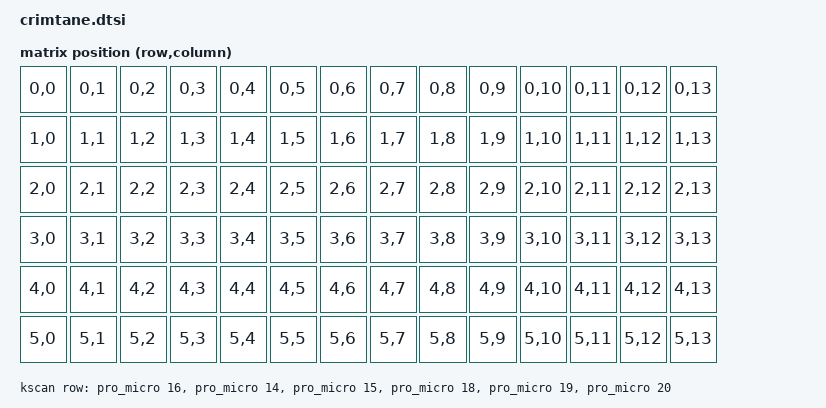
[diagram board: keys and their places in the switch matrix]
// This file was generated from a template. Edit it to match your keyboard.
// See https://zmk.dev/docs/development/hardware-integration/new-shield for more
// instructions.

#include <dt-bindings/zmk/matrix_transform.h>

#include "crimtane-layouts.dtsi"

/ {
    chosen {
        zmk,kscan = &kscan;
        zmk,matrix_transform = &default_transform;
    };

    default_transform: default_transform {
        compatible = "zmk,matrix-transform";
        columns = <14>;
        rows = <6>;
//  nice!nano_v2
// | 024,010 | 100,010 | 011,010 | 104,010 | 106,010 | 022,010 | 020,010 |	| 106,010 | 104,010 | 011,010 | 100,010 | 024,010 | 022,010 | 020,010 |
// | 024,111 | 100,111 | 011,111 | 104,111 | 106,111 | 022,111 |			  | 104,111 | 011,111 | 100,111 | 024,111 | 022,111 | 020,111 |
// | 024,113 | 100,113 | 011,113 | 104,113 | 106,113 | 022,113 | 020,113 |	| 106,113 | 104,113 | 011,113 | 100,113 | 024,113 | 022,113 | 020,113 |
// | 024,115 | 100,115 | 011,115 | 104,115 | 106,115 | 022,115 | 020,115 |	| 106,115 | 104,115 | 011,115 | 100,115 | 024,115 | 022,115 | 020,115 |
// | 024,002 | 100,002 | 011,002 | 104,002 | 106,002 | 022,002 |			  | 104,002 | 011,002 | 100,002 | 024,002 | 022,002 | 020,002 |
// | 024,029 | 100,029 | 011,029 | 104,029 | 106,029 |	       | 020,029 |	| 106,029 |         | 011,029 | 100,029 | 024,029 | 022,029 | 020,029 |
//  pro_micro
// | 5,16 |  6,16 |  7,16 |  8,16 |  9,16 |  4,16 |  3,16 |   |  9,16 |  8,16 |  7,16 |  6,16 |  5,16 |  4,16 |  3,16 |
// | 5,14 |  6,14 |  7,14 |  8,14 |  9,14 |  4,14 |       |           |  8,14 |  7,14 |  6,14 |  5,14 |  4,14 |  3,14 |
// | 5,15 |  6,15 |  7,15 |  8,15 |  9,15 |  4,15 |  3,15 |   |  9,15 |  8,15 |  7,15 |  6,15 |  5,15 |  4,15 |  3,15 |
// | 5,18 |  6,18 |  7,18 |  8,18 |  9,18 |  4,18 |  3,18 |   |  9,18 |  8,18 |  7,18 |  6,18 |  5,18 |  4,18 |  3,18 |
// | 5,19 |  6,19 |  7,19 |  8,19 |  9,19 |  4,19 |       |           |  8,19 |  7,19 |  6,19 |  5,19 |  4,19 |  3,19 |
// | 5,20 |  6,20 |  7,20 |  8,20 |  9,20 |       |  3,20 |   |  9,20 |       |  7,20 |  6,20 |  5,20 |  4,20 |  3,20 |

        map = <
RC(0,0) RC(0,1) RC(0,2) RC(0,3) RC(0,4) RC(0,5) RC(0,6) 	RC(0,7) RC(0,8) RC(0,9) RC(0,10) RC(0,11) RC(0,12) RC(0,13)
RC(1,0) RC(1,1) RC(1,2) RC(1,3) RC(1,4) RC(1,5) RC(1,6)	 	RC(1,7)	RC(1,8) RC(1,9) RC(1,10) RC(1,11) RC(1,12) RC(1,13)
RC(2,0) RC(2,1) RC(2,2) RC(2,3) RC(2,4) RC(2,5) RC(2,6) 	RC(2,7) RC(2,8) RC(2,9) RC(2,10) RC(2,11) RC(2,12) RC(2,13)
RC(3,0) RC(3,1) RC(3,2) RC(3,3) RC(3,4) RC(3,5) RC(3,6) 	RC(3,7) RC(3,8) RC(3,9) RC(3,10) RC(3,11) RC(3,12) RC(3,13)
RC(4,0) RC(4,1) RC(4,2) RC(4,3) RC(4,4) RC(4,5) RC(4,6)	 	RC(4,7)	RC(4,8) RC(4,9) RC(4,10) RC(4,11) RC(4,12) RC(4,13)
RC(5,0) RC(5,1) RC(5,2) RC(5,3) RC(5,4) RC(5,5)	RC(5,6) 	RC(5,7) RC(5,8)	RC(5,9) RC(5,10) RC(5,11) RC(5,12) RC(5,13)
        >;
    };

kscan: kscan {
        compatible = "zmk,kscan-gpio-matrix";
        diode-direction = "col2row";

        // Your 6 Row Pins (Corrected based on [col, row])
        row-gpios
            = <&pro_micro 16 (GPIO_ACTIVE_HIGH | GPIO_PULL_DOWN)> // Row 16 (nice!nano: 010)
            , <&pro_micro 14 (GPIO_ACTIVE_HIGH | GPIO_PULL_DOWN)> // Row 14 (nice!nano: 111)
            , <&pro_micro 15 (GPIO_ACTIVE_HIGH | GPIO_PULL_DOWN)> // Row 15 (nice!nano: 113)
            , <&pro_micro 18 (GPIO_ACTIVE_HIGH | GPIO_PULL_DOWN)> // Row 18 (nice!nano: 115)
            , <&pro_micro 19 (GPIO_ACTIVE_HIGH | GPIO_PULL_DOWN)> // Row 19 (nice!nano: 002)
            , <&pro_micro 20 (GPIO_ACTIVE_HIGH | GPIO_PULL_DOWN)> // Row 20 (nice!nano: 029)
            ;

    };
};
